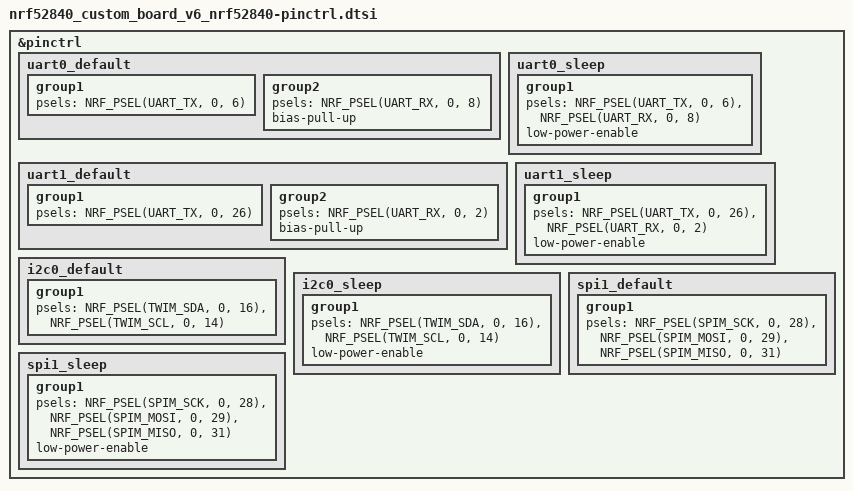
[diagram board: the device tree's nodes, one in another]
/*
 * Copyright (c) 2022 Nordic Semiconductor
 * SPDX-License-Identifier: Apache-2.0
 */

&pinctrl {
	uart0_default: uart0_default {
		group1 {
			psels = <NRF_PSEL(UART_TX, 0, 6)>;
		};
		group2 {
			psels = <NRF_PSEL(UART_RX, 0, 8)>;
			bias-pull-up;
		};
	};

	uart0_sleep: uart0_sleep {
		group1 {
			psels = <NRF_PSEL(UART_TX, 0, 6)>,
				<NRF_PSEL(UART_RX, 0, 8)>;
			low-power-enable;
		};
	};

	uart1_default: uart1_default {
		group1 {
			psels = <NRF_PSEL(UART_TX, 0, 26)>;
		};
		group2 {
			psels = <NRF_PSEL(UART_RX, 0, 2)>;
			bias-pull-up;
		};
	};

	uart1_sleep: uart1_sleep {
		group1 {
			psels = <NRF_PSEL(UART_TX, 0, 26)>,
				<NRF_PSEL(UART_RX, 0, 2)>;
			low-power-enable;
		};
	};

	i2c0_default: i2c0_default {
		group1 {
			psels = <NRF_PSEL(TWIM_SDA, 0, 16)>,				//assign SDA to P0.16
				<NRF_PSEL(TWIM_SCL, 0, 14)>;					//assign SCL to P0.14
		};
	};

	i2c0_sleep: i2c0_sleep {
		group1 {
			psels = <NRF_PSEL(TWIM_SDA, 0, 16)>,
				<NRF_PSEL(TWIM_SCL, 0, 14)>;
			low-power-enable;
		};
	};

	spi1_default: spi1_default {
		group1 {
			psels = <NRF_PSEL(SPIM_SCK, 0, 28)>, 					
					<NRF_PSEL(SPIM_MOSI, 0, 29)>,					
					<NRF_PSEL(SPIM_MISO, 0, 31)>;					
		};
	};

	spi1_sleep: spi1_sleep {
		group1 {
			psels = <NRF_PSEL(SPIM_SCK, 0, 28)>, 					
					<NRF_PSEL(SPIM_MOSI, 0, 29)>,					
					<NRF_PSEL(SPIM_MISO, 0, 31)>;					
			low-power-enable;
		};
	};

};
